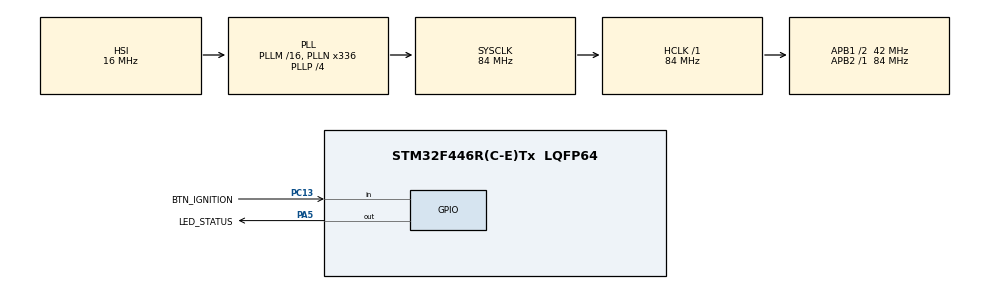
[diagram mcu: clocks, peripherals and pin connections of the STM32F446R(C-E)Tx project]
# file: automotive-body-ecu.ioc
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Mcu.Family=STM32F4
Mcu.Name=STM32F446R(C-E)Tx
Mcu.Package=LQFP64
NUCLEO-F446RE.BUTTON=1
NUCLEO-F446RE.Bsp_Common_DEMO=true
NUCLEO-F446RE.LD1=true
NVIC.EXTI15_10_IRQn=true\:0\:0\:false\:false\:true\:false\:true\:true
NVIC.PriorityGroup=NVIC_PRIORITYGROUP_0
PA13.GPIO_Label=TMS
PA13.Signal=SYS_JTMS-SWDIO
PA14.GPIO_Label=TCK
PA14.Signal=SYS_JTCK-SWCLK
PA2.GPIO_Label=USART_TX
PA2.Signal=USART2_TX
PA3.GPIO_Label=USART_RX
PA3.Signal=USART2_RX
PA5.GPIO_Label=LED_STATUS
PA5.Signal=GPIO_Output
PB3.GPIO_Label=SWO
PB3.Signal=SYS_JTDO-SWO
PC13.GPIO_Label=BTN_IGNITION
PC13.Signal=GPIO_Input
PC14-OSC32_IN.Signal=RCC_OSC32_IN
PC15-OSC32_OUT.Signal=RCC_OSC32_OUT
PH0-OSC_IN.Signal=RCC_OSC_IN
PH1-OSC_OUT.Signal=RCC_OSC_OUT
ProjectManager.HeapSize=0x200
ProjectManager.StackSize=0x400
ProjectManager.TargetToolchain=STM32CubeIDE
RCC.AHBFreq_Value=84000000
RCC.APB1CLKDivider=RCC_HCLK_DIV2
RCC.APB1Freq_Value=42000000
RCC.APB1TimFreq_Value=84000000
RCC.APB2Freq_Value=84000000
RCC.APB2TimFreq_Value=84000000
RCC.CortexFreq_Value=84000000
RCC.FLatency-AdvancedSettings=FLASH_LATENCY_2
RCC.HCLKFreq_Value=84000000
RCC.HSE_VALUE=8000000
RCC.HSI_VALUE=16000000
RCC.LSE_VALUE=32768
RCC.PLLN=336
RCC.PLLP=RCC_PLLP_DIV4
RCC.SYSCLKFreq_VALUE=84000000
RCC.SYSCLKSource=RCC_SYSCLKSOURCE_PLLCLK
RCC.USBFreq_Value=168000000
RCC.VCOOutputFreq_Value=336000000
VP_NUCLEO-F446RE_VS_BSP_COMMON.Mode=COMMON
board=NUCLEO-F446RE

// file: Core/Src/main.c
/* USER CODE BEGIN Header */
/**
  ******************************************************************************
  * @file           : main.c
  * @brief          : Main program body
  ******************************************************************************
  * @attention
  *
  * Copyright (c) 2026 STMicroelectronics.
  * All rights reserved.
  *
  * This software is licensed under terms that can be found in the LICENSE file
  * in the root directory of this software component.
  * If no LICENSE file comes with this software, it is provided AS-IS.
  *
  ******************************************************************************
  */
/* USER CODE END Header */
#include "main.h"

/* USER CODE BEGIN Includes */
#include "body_control.h"
#include "logger.h"
#include "scheduler.h"
#include "watchdog_driver.h"
/* USER CODE END Includes */

/* Button state */

#define BUTTON_RELEASED                    0U
#define BUTTON_PRESSED                     1U

__IO uint32_t BspButtonState = BUTTON_RELEASED;

/* USER CODE BEGIN PV */

/* Reset cause, captured before anything has a chance to clear the RCC flags.
 * A watchdog reset means the previous run stopped responding - the single
 * most important fact in the whole startup log. */
static bool s_reset_by_watchdog = false;

/* USER CODE END PV */

void SystemClock_Config(void);
static void MX_GPIO_Init(void);

int main(void)
{

  /* USER CODE BEGIN 1 */

  /* Read the reset cause first. The RCC reset flags are sticky across resets
   * and are only cleared by software, so they must be sampled before any
   * other code has a chance to touch them - and then cleared, or every
   * subsequent boot would look like a watchdog reset. */
  s_reset_by_watchdog = WatchdogDriver_WasResetByWatchdog();
  WatchdogDriver_ClearResetFlags();

  /* USER CODE END 1 */

  /* MCU Configuration--------------------------------------------------------*/

  /* Reset of all peripherals, Initializes the Flash interface and the Systick. */
  HAL_Init();

  /* Configure the system clock */
  SystemClock_Config();

  /* Initialize all configured peripherals */
  MX_GPIO_Init();
  /* USER CODE BEGIN 2 */

  /* Deliberately empty. The ECU is brought up in the "USER CODE BEGIN BSP"
   * section below instead, because the BSP_LED_Init() and BSP_PB_Init() calls
   * that CubeMX places between here and there reconfigure PA5 and PC13 and
   * would overwrite our own pin configuration. Initialising after them means
   * our configuration is the one that survives. */

  /* USER CODE END 2 */

  /* Initialize leds */
  BSP_LED_Init(LED2);

  /* Initialize USER push-button, will be used to trigger an interrupt each time it's pressed.*/
  BSP_PB_Init(BUTTON_USER, BUTTON_MODE_EXTI);

  /* USER CODE BEGIN BSP */

  /* ------------------------------------------------------------------------
   * ECU start-up
   *
   * Everything below replaces the CubeMX board-demo code. It runs here, after
   * the BSP has finished touching PA5 and PC13, so that the pin configuration
   * installed by our own drivers is the one that takes effect.
   * --------------------------------------------------------------------- */

  (void)BodyControl_Init(s_reset_by_watchdog);

  if (!BodyControl_IsHealthy())
  {
      LOG_WARN("One or more subsystems failed to initialise - running degraded");
  }

  /* The watchdog is armed LAST, once every subsystem is up. Arming it earlier
   * would let a slow initialisation trigger a reset and leave the ECU in a
   * boot loop that looks exactly like a firmware hang.
   *
   * From this point the main loop must refresh it within the timeout or the
   * MCU resets. That is the intended contract, not a hazard. */
  if (!WatchdogDriver_Init())
  {
      LOG_ERROR("Watchdog failed to start - no hang protection active");
  }

  /* USER CODE END BSP */

  /* Infinite loop */
  /* USER CODE BEGIN WHILE */
  while (1)
  {
      /* ------------------------------------------------------------------
       * The entire ECU runs from these two lines.
       *
       * Scheduler_Run() executes whichever registered tasks have come due
       * and returns immediately when none have. There is no delay here: the
       * loop spins freely, which is what keeps activation jitter down to the
       * duration of a single task rather than the length of a delay.
       *
       * WatchdogDriver_Refresh() is deliberately placed AFTER the scheduler,
       * and deliberately nowhere else. If any task hangs, the scheduler never
       * returns, the refresh never happens, and the watchdog resets the ECU -
       * which is precisely the behaviour we want.
       *
       * Refreshing from a timer interrupt instead would keep petting the
       * watchdog even while the main loop was dead, defeating the entire
       * mechanism. That mistake is common enough to be worth naming here.
       * ------------------------------------------------------------------ */

      Scheduler_Run();

      WatchdogDriver_Refresh();

    /* USER CODE END WHILE */

  }
}

void SystemClock_Config(void)
{
  RCC_OscInitTypeDef RCC_OscInitStruct = {0};
  RCC_ClkInitTypeDef RCC_ClkInitStruct = {0};

  /** Configure the main internal regulator output voltage
  */
  __HAL_RCC_PWR_CLK_ENABLE();
  __HAL_PWR_VOLTAGESCALING_CONFIG(PWR_REGULATOR_VOLTAGE_SCALE3);

  /** Initializes the RCC Oscillators according to the specified parameters
  * in the RCC_OscInitTypeDef structure.
  */
  RCC_OscInitStruct.OscillatorType = RCC_OSCILLATORTYPE_HSI;
  RCC_OscInitStruct.HSIState = RCC_HSI_ON;
  RCC_OscInitStruct.HSICalibrationValue = RCC_HSICALIBRATION_DEFAULT;
  RCC_OscInitStruct.PLL.PLLState = RCC_PLL_ON;
  RCC_OscInitStruct.PLL.PLLSource = RCC_PLLSOURCE_HSI;
  RCC_OscInitStruct.PLL.PLLM = 16;
  RCC_OscInitStruct.PLL.PLLN = 336;
  RCC_OscInitStruct.PLL.PLLP = RCC_PLLP_DIV4;
  RCC_OscInitStruct.PLL.PLLQ = 2;
  RCC_OscInitStruct.PLL.PLLR = 2;
  if (HAL_RCC_OscConfig(&RCC_OscInitStruct) != HAL_OK)
  {
    Error_Handler();
  }

  /** Initializes the CPU, AHB and APB buses clocks
  */
  RCC_ClkInitStruct.ClockType = RCC_CLOCKTYPE_HCLK|RCC_CLOCKTYPE_SYSCLK
                              |RCC_CLOCKTYPE_PCLK1|RCC_CLOCKTYPE_PCLK2;
  RCC_ClkInitStruct.SYSCLKSource = RCC_SYSCLKSOURCE_PLLCLK;
  RCC_ClkInitStruct.AHBCLKDivider = RCC_SYSCLK_DIV1;
  RCC_ClkInitStruct.APB1CLKDivider = RCC_HCLK_DIV2;
  RCC_ClkInitStruct.APB2CLKDivider = RCC_HCLK_DIV1;

  if (HAL_RCC_ClockConfig(&RCC_ClkInitStruct, FLASH_LATENCY_2) != HAL_OK)
  {
    Error_Handler();
  }
}

static void MX_GPIO_Init(void)
{
  GPIO_InitTypeDef GPIO_InitStruct = {0};

  /* GPIO Ports Clock Enable */
  __HAL_RCC_GPIOC_CLK_ENABLE();
  __HAL_RCC_GPIOH_CLK_ENABLE();
  __HAL_RCC_GPIOA_CLK_ENABLE();
  __HAL_RCC_GPIOB_CLK_ENABLE();

  /*Configure GPIO pin Output Level */
  HAL_GPIO_WritePin(LED_STATUS_GPIO_Port, LED_STATUS_Pin, GPIO_PIN_RESET);

  /*Configure GPIO pin : BTN_IGNITION_Pin */
  GPIO_InitStruct.Pin = BTN_IGNITION_Pin;
  GPIO_InitStruct.Mode = GPIO_MODE_INPUT;
  GPIO_InitStruct.Pull = GPIO_NOPULL;
  HAL_GPIO_Init(BTN_IGNITION_GPIO_Port, &GPIO_InitStruct);

  /*Configure GPIO pins : USART_TX_Pin USART_RX_Pin */
  GPIO_InitStruct.Pin = USART_TX_Pin|USART_RX_Pin;
  GPIO_InitStruct.Mode = GPIO_MODE_AF_PP;
  GPIO_InitStruct.Pull = GPIO_NOPULL;
  GPIO_InitStruct.Speed = GPIO_SPEED_FREQ_VERY_HIGH;
  GPIO_InitStruct.Alternate = GPIO_AF7_USART2;
  HAL_GPIO_Init(GPIOA, &GPIO_InitStruct);

  /*Configure GPIO pin : LED_STATUS_Pin */
  GPIO_InitStruct.Pin = LED_STATUS_Pin;
  GPIO_InitStruct.Mode = GPIO_MODE_OUTPUT_PP;
  GPIO_InitStruct.Pull = GPIO_NOPULL;
  GPIO_InitStruct.Speed = GPIO_SPEED_FREQ_LOW;
  HAL_GPIO_Init(LED_STATUS_GPIO_Port, &GPIO_InitStruct);

}

/**
  * @brief EXTI line detection callbacks
  * @param GPIO_Pin: Specifies the pins connected EXTI line
  * @retval None
  */
void HAL_GPIO_EXTI_Callback(uint16_t GPIO_Pin)
{
  if(GPIO_Pin==USER_BUTTON_PIN)
  {
    BspButtonState = BUTTON_PRESSED;
  }
}

void Error_Handler(void)
{
  __disable_irq();
  while (1)
  {
  }
}
